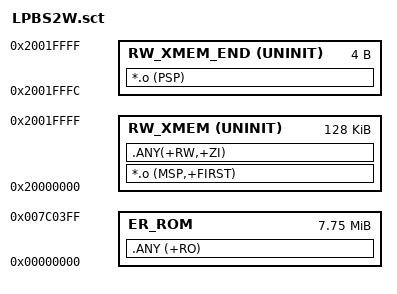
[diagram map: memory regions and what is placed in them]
; *************************************************************
; *** Scatter-Loading Description File generated by uVision ***
; *************************************************************
LR_FLASH 0x00000000 0x00800000  {;load region size_region
	ER_ROM 0x00000000 0x00800000 - 255 * 1024  {;execution address = load address
		*.o(EXCEPT_VECTS,+First)
		*(InRoot$$Sections)
		*.o (CACHE.4KBMEM)
		}
		
	ER_MACH + 0 {*.o (.mach.init)}
	ER_MACH0 + 0 {*.o (.mach0.init) }
	ER_MACH1 + 0 {*.o (.mach1.init) }
	ER_MACH2 + 0 {*.o (.mach2.init) }
	ER_MACH3 + 0 {*.o (.mach3.init) }
	ER_MACH4 + 0 {*.o (.mach4.init) }
	ER_MACH5 + 0 {*.o (.mach5.init) }
	ER_MACH6 + 0 {*.o (.mach6.init) }
	ER_MACH7 + 0 {*.o (.mach7.init) }
	ER_MACH8 + 0 {*.o (.mach8.init) }
	ER_MACH9 + 0 {*.o (.mach9.init) } 
	
	ER_SHELL0 + 0 {*.o (.shell0.cmd)}
	ER_SHELL1 + 0 {*.o (.shell1.cmd)}
	ER_SHELL2 + 0 {*.o (.shell2.cmd)}

	ER_STUB + 0 {*.o (.sched.stub)}
	
	ER_ANY + 0 {.ANY (+RO)}
	
    RW_XMEM 0x20000000 UNINIT 0x20000  {;64+32+32KB XVPMEM
		*.o (MSP,+FIRST)
		.ANY(+RW,+ZI)
	}

    RW_XMEM_END 0x20020000 - 4 UNINIT 4{
		*.o (PSP)
	}
}


